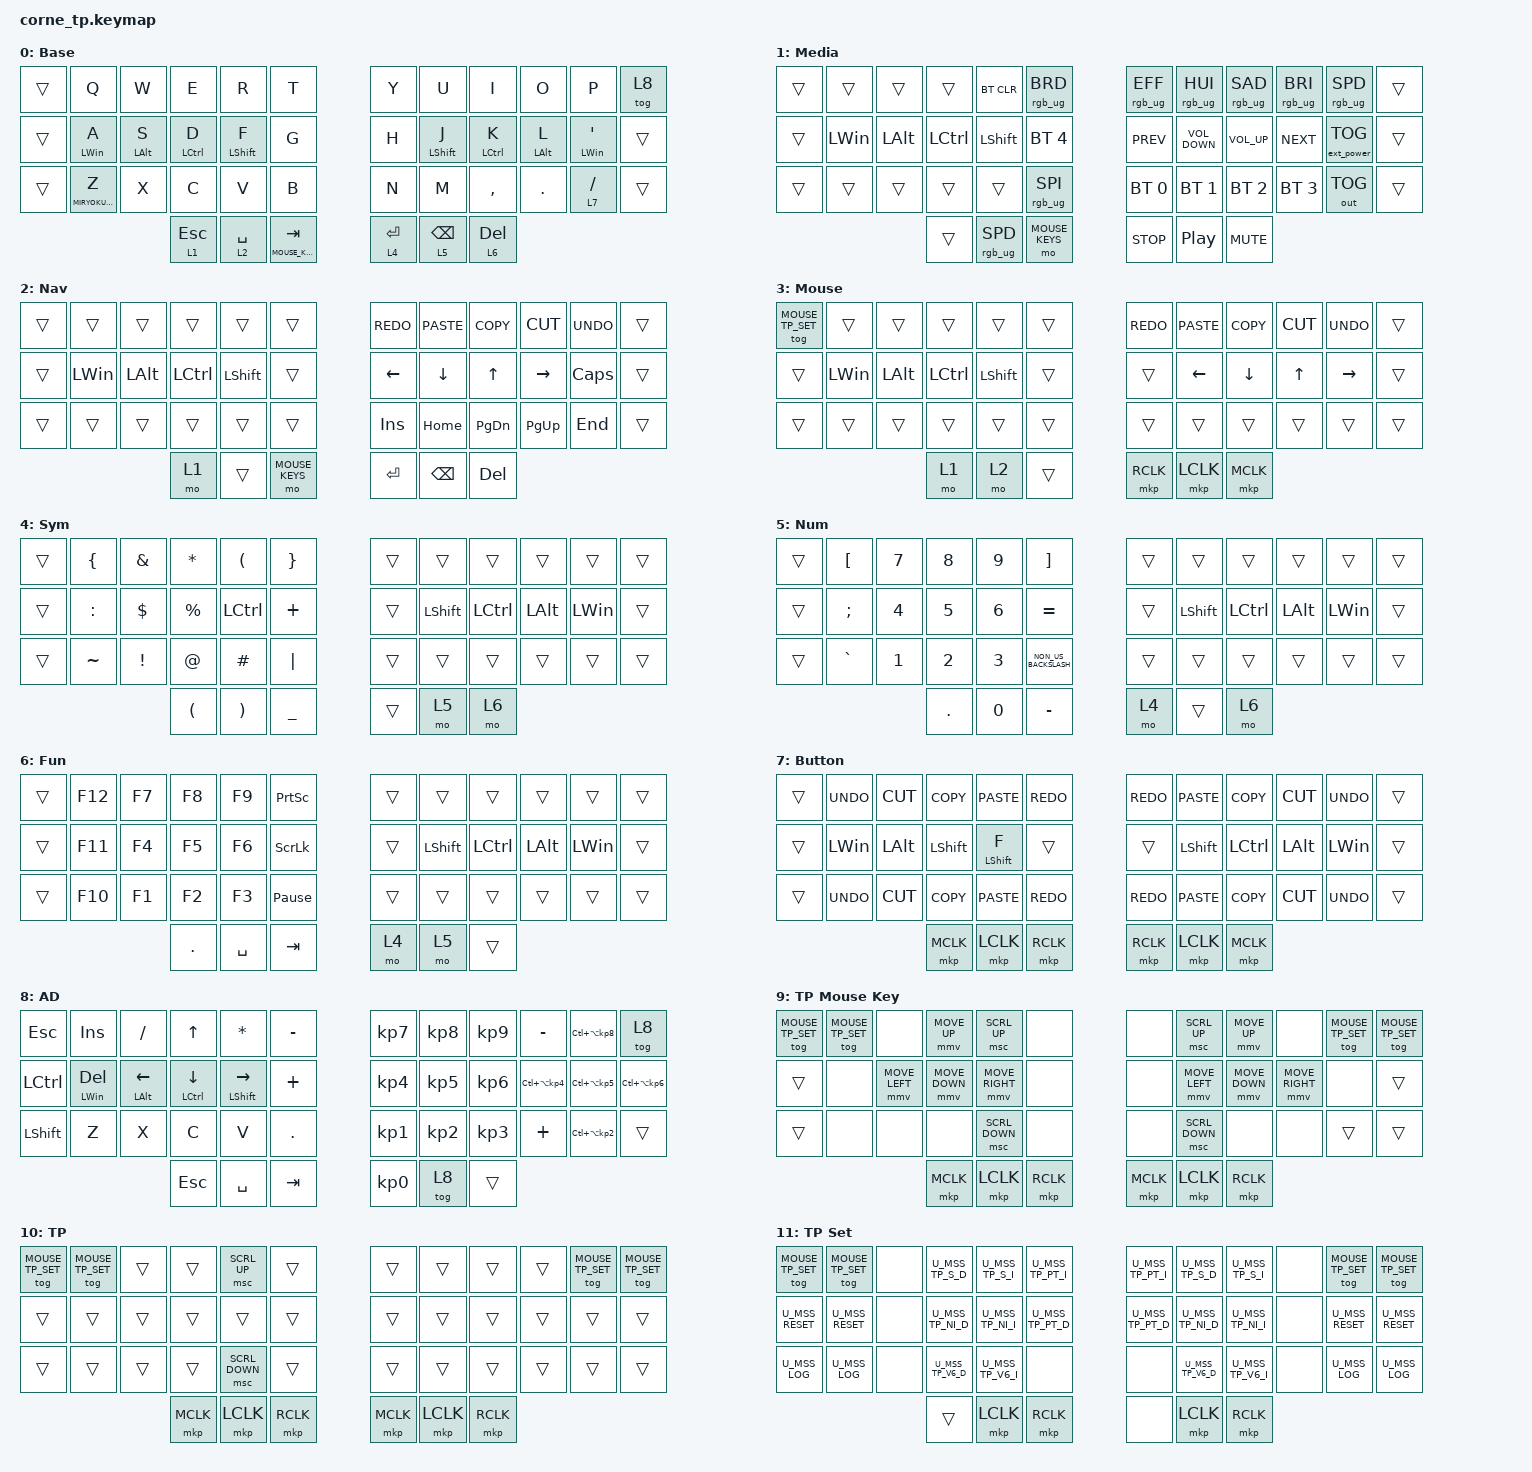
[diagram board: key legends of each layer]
/*
 * Copyright (c) 2020 The ZMK Contributors
 *
 * SPDX-License-Identifier: MIT
 */

#include <behaviors.dtsi>
#include <dt-bindings/zmk/keys.h>
#include <dt-bindings/zmk/bt.h>
// 我添加的头文件
#include <dt-bindings/zmk/mouse.h>
#include <behaviors.dtsi>
#include <dt-bindings/zmk/ext_power.h>
#include <dt-bindings/zmk/outputs.h>
#include <dt-bindings/zmk/rgb.h>

#define BASE 0
#define MIRYOKU_BASE 0
#define MIRYOKU_MEDIA 1
#define MIRYOKU_NAV 2
#define MIRYOKU_MOUSE 3
#define MIRYOKU_SYM 4
#define MIRYOKU_NUM 5
#define MIRYOKU_FUN 6
#define MIRYOKU_BUTTON 7
#define MIRYOKU_APP_AD 8
#define MOUSE_KEYS 9
#define MOUSE_TP 10
#define MOUSE_TP_SET 11

/*
 * Defines to enable/disable features
 *
 * These defines allow us to conditionally enable and disable parts of the keymap config.
 *
 * For example, if we decide to build the firmware without the mouse features, we can
 * disable all the config options that rely on those forks and modules without having
 * to edit the entire keymap file manually every time.
 */

#define HAS_MOUSE_KEYS
#define HAS_MOUSE_TP

#ifdef HAS_MOUSE_KEYS
  #include <dt-bindings/zmk/mouse.h>
  #include <behaviors/mouse_keys.dtsi>
#endif  // HAS_MOUSE_KEYS

#ifdef HAS_MOUSE_TP
  // We store the trackpoint settings in a separate file
  // to make organization a little easier.
  #include "include/mouse_tp.dtsi"
#endif  // HAS_MOUSE_TP



// Adjust layer keys based on enabled features.
//
// This prevents build errors when we build the firmware
// without the mouse keys PR or the TP module.
#ifdef HAS_MOUSE_KEYS
  #define U_THUMB_INNER &mo MOUSE_KEYS
#else
  #define U_THUMB_INNER &none
#endif  // HAS_MOUSE_KEYS

#ifdef HAS_MOUSE_TP
  #define U_TOG_TP_SET &tog MOUSE_TP_SET
#else
  #define U_TOG_TP_SET &none
#endif  // HAS_MOUSE_TP

// Disable line-wrap in your editor to see a "visualization" of the key layouts
/ {
  behaviors {
    u_mt: u_mt {
      compatible = "zmk,behavior-hold-tap";
      #binding-cells = <2>;
      tapping-term-ms = <200>;
      flavor = "tap-preferred";
      bindings = <&kp>, <&kp>;
    };
    u_lt: u_lt {
      compatible = "zmk,behavior-hold-tap";
      #binding-cells = <2>;
      tapping-term-ms = <200>;
      flavor = "tap-preferred";
      bindings = <&mo>, <&kp>;
    };
  };
  keymap {
    compatible = "zmk,keymap";

        default_layer {
            display-name = "Base";
            bindings = <
&trans  &kp Q                        &kp W       &kp E        &kp R         &kp T                 &kp Y      &kp U            &kp I         &kp O       &kp P         &tog 8
&trans  &mt LEFT_WIN A               &mt LALT S  &mt LCTRL D  &mt LSHIFT F  &kp G                 &kp H      &mt LSHIFT J     &mt LCTRL K   &mt LALT L  &mt LWIN SQT  &trans
&trans  &lt MIRYOKU_BUTTON Z         &kp X       &kp C        &kp V         &kp B                 &kp N      &kp M            &kp COMMA     &kp DOT     &lt 7 FSLH    &trans
                                     &lt 1 ESC    &lt 2 SPACE   &lt MOUSE_KEYS TAB                &lt 4 RET  &lt 5 BACKSPACE  &lt 6 DELETE
            >;
        };

        media_layer {
            display-name = "Media";
            bindings = <
&trans  &trans        &trans    &trans     &bt BT_CLR            &rgb_ug RGB_BRD              &rgb_ug RGB_EFF    &rgb_ug RGB_HUI    &rgb_ug RGB_SAD    &rgb_ug RGB_BRI  &rgb_ug RGB_SPD    &trans
&trans  &kp LEFT_WIN  &kp LALT  &kp LCTRL  &kp LSHIFT            &bt BT_SEL 4                 &kp K_PREV         &kp C_VOLUME_DOWN  &kp C_VOLUME_UP    &kp K_NEXT       &ext_power EP_TOG  &trans
&trans  &trans        &trans    &trans     &trans                &rgb_ug RGB_SPI              &bt BT_SEL 0       &bt BT_SEL 1       &bt BT_SEL 2       &bt BT_SEL 3     &out OUT_TOG       &trans
                                &trans     &rgb_ug RGB_SPD       &mo MOUSE_KEYS               &kp C_STOP         &kp C_PLAY_PAUSE   &kp K_MUTE
            >;
        };

        nav_layer {
            display-name = "Nav";
            bindings = <
&trans  &trans        &trans    &trans     &trans      &trans             &kp K_REDO      &kp K_PASTE     &kp K_COPY     &kp K_CUT        &kp K_UNDO    &trans
&trans  &kp LEFT_WIN  &kp LALT  &kp LCTRL  &kp LSHIFT  &trans             &kp LEFT_ARROW  &kp DOWN_ARROW  &kp UP_ARROW   &kp RIGHT_ARROW  &kp CAPSLOCK  &trans
&trans  &trans        &trans    &trans     &trans      &trans             &kp INSERT      &kp HOME        &kp PAGE_DOWN  &kp PAGE_UP      &kp END       &trans
                                &mo 1      &trans      &mo MOUSE_KEYS     &kp ENTER       &kp BACKSPACE   &kp DEL
            >;
        };

        mouse_layer {
            display-name = "Mouse";
            bindings = <
&tog MOUSE_TP_SET  &trans        &trans    &trans     &trans      &trans    &kp K_REDO  &kp K_PASTE     &kp K_COPY      &kp K_CUT     &kp K_UNDO       &trans
&trans             &kp LEFT_WIN  &kp LALT  &kp LCTRL  &kp LSHIFT  &trans    &trans      &kp LEFT_ARROW  &kp DOWN_ARROW  &kp UP_ARROW  &kp RIGHT_ARROW  &trans
&trans             &trans        &trans    &trans     &trans      &trans    &trans      &trans          &trans          &trans        &trans           &trans
                                           &mo 1      &mo 2       &trans    &mkp RCLK   &mkp LCLK       &mkp MCLK
            >;
        };

        sym_layer {
            display-name = "Sym";
            bindings = <
&trans  &kp LEFT_BRACE  &kp AMPERSAND    &kp ASTERISK          &kp LEFT_PARENTHESIS   &kp RIGHT_BRACE    &trans  &trans      &trans     &trans    &trans        &trans
&trans  &kp COLON       &kp DOLLAR       &kp PERCENT           &kp LCTRL              &kp PLUS           &trans  &kp LSHIFT  &kp LCTRL  &kp LALT  &kp LEFT_WIN  &trans
&trans  &kp TILDE       &kp EXCLAMATION  &kp AT_SIGN           &kp HASH               &kp PIPE           &trans  &trans      &trans     &trans    &trans        &trans
                                         &kp LEFT_PARENTHESIS  &kp RIGHT_PARENTHESIS  &kp UNDERSCORE     &trans  &mo 5       &mo 6
            >;
        };

        num_layer {
            display-name = "Num";
            bindings = <
&trans  &kp LEFT_BRACKET  &kp NUMBER_7  &kp NUMBER_8  &kp NUMBER_9  &kp RIGHT_BRACKET       &trans  &trans      &trans     &trans    &trans        &trans
&trans  &kp SEMICOLON     &kp NUMBER_4  &kp NUMBER_5  &kp NUMBER_6  &kp EQUAL               &trans  &kp LSHIFT  &kp LCTRL  &kp LALT  &kp LEFT_WIN  &trans
&trans  &kp GRAVE         &kp NUMBER_1  &kp NUMBER_2  &kp NUMBER_3  &kp NON_US_BACKSLASH    &trans  &trans      &trans     &trans    &trans        &trans
                                        &kp PERIOD    &kp N0        &kp MINUS               &mo 4   &trans      &mo 6
            >;
        };

        fun_layer {
            display-name = "Fun";
            bindings = <
&trans  &kp F12  &kp F7  &kp F8      &kp F9     &kp PRINTSCREEN    &trans  &trans      &trans     &trans    &trans        &trans
&trans  &kp F11  &kp F4  &kp F5      &kp F6     &kp SCROLLLOCK     &trans  &kp LSHIFT  &kp LCTRL  &kp LALT  &kp LEFT_WIN  &trans
&trans  &kp F10  &kp F1  &kp F2      &kp F3     &kp PAUSE_BREAK    &trans  &trans      &trans     &trans    &trans        &trans
                         &kp PERIOD  &kp SPACE  &kp TAB            &mo 4   &mo 5       &trans
            >;
        };

        button_layer {
            display-name = "Button";
            bindings = <
&trans  &kp K_UNDO    &kp K_CUT     &kp K_COPY  &kp K_PASTE   &kp K_REDO    &kp K_REDO  &kp K_PASTE  &kp K_COPY  &kp K_CUT     &kp K_UNDO    &trans
&trans  &kp LEFT_WIN  &kp LEFT_ALT  &kp LSHIFT  &mt LSHIFT F  &trans        &trans      &kp LSHIFT   &kp LCTRL   &kp LEFT_ALT  &kp LEFT_WIN  &trans
&trans  &kp K_UNDO    &kp K_CUT     &kp K_COPY  &kp K_PASTE   &kp K_REDO    &kp K_REDO  &kp K_PASTE  &kp K_COPY  &kp K_CUT     &kp K_UNDO    &trans
                                    &mkp MCLK   &mkp LCLK     &mkp RCLK     &mkp RCLK   &mkp LCLK    &mkp MCLK
            >;
        };

        ad_layer {
            display-name = "AD";
            bindings = <
&kp ESC         &kp INS           &kp FSLH                 &kp UP                &kp ASTERISK            &kp MINUS     &kp KP_NUMBER_7  &kp KP_NUMBER_8  &kp KP_NUMBER_9  &kp MINUS                &kp LC(LA(KP_NUMBER_8))  &tog 8
&kp LCTRL       &mt LEFT_WIN DEL  &mt LEFT_ALT LEFT_ARROW  &mt LCTRL DOWN_ARROW  &mt LSHIFT RIGHT_ARROW  &kp PLUS      &kp KP_NUMBER_4  &kp KP_NUMBER_5  &kp KP_NUMBER_6  &kp LC(LA(KP_NUMBER_4))  &kp LC(LA(KP_NUMBER_5))  &kp LC(LA(KP_NUMBER_6))
&kp LEFT_SHIFT  &kp Z             &kp X                    &kp C                 &kp V                   &kp PERIOD    &kp KP_NUMBER_1  &kp KP_NUMBER_2  &kp KP_NUMBER_3  &kp PLUS                 &kp LC(LA(KP_NUMBER_2))  &trans
                                                           &kp ESC               &kp SPACE               &kp TAB       &kp KP_NUMBER_0  &tog 8           &trans
            >;
        };

#ifdef HAS_MOUSE_KEYS

    MouseKeys_layer {
      display-name = "TP Mouse Key";
      bindings = <
// ╭────────────────────────┬────────────────────────┬────────────────────────┬────────────────────────┬────────────────────────┬────────────────────────╮    ╭────────────────────────┬────────────────────────┬────────────────────────┬────────────────────────┬────────────────────────┬────────────────────────╮
     U_TOG_TP_SET             U_TOG_TP_SET             &none                    &mmv MOVE_UP             &msc SCRL_UP             &none                         &none                    &msc SCRL_UP             &mmv MOVE_UP             &none                    U_TOG_TP_SET              U_TOG_TP_SET
// ├────────────────────────┼────────────────────────┼────────────────────────┼────────────────────────┼────────────────────────┼────────────────────────┤    ├────────────────────────┼────────────────────────┼────────────────────────┼────────────────────────┼────────────────────────┼────────────────────────┤
     &trans                   &none                    &mmv MOVE_LEFT           &mmv MOVE_DOWN           &mmv MOVE_RIGHT          &none                         &none                    &mmv MOVE_LEFT           &mmv MOVE_DOWN           &mmv MOVE_RIGHT          &none                     &trans
// ├────────────────────────┼────────────────────────┼────────────────────────┼────────────────────────┼────────────────────────┼────────────────────────┤    ├────────────────────────┼────────────────────────┼────────────────────────┼────────────────────────┼────────────────────────┼────────────────────────┤
     &trans                   &none                    &none                    &none                    &msc SCRL_DOWN           &none                         &none                    &msc SCRL_DOWN           &none                    &none                    &trans                    &trans
// ╰────────────────────────┴────────────────────────┴────────────────────────┴────────────────────────┼────────────────────────┼────────────────────────┤    ├────────────────────────┼────────────────────────┼────────────────────────┼────────────────────────┴────────────────────────┼────────────────────────╯
                                                                                &mkp MCLK                &mkp LCLK                &mkp RCLK                     &mkp MCLK                &mkp LCLK                &mkp RCLK
//                                                                            ╰────────────────────────┴────────────────────────┴────────────────────────╯    ╰────────────────────────┴────────────────────────┴────────────────────────╯
      >;
    };

#endif

#ifdef HAS_MOUSE_TP

    // Automatically activated when the mouse or trackpoint moves.
    // Configured in `include/mouse_tp.dtsi`.
    MouseTP_layer {
      display-name = "TP";
      bindings = <
// ╭────────────────────────┬────────────────────────┬────────────────────────┬────────────────────────┬────────────────────────┬────────────────────────╮    ╭────────────────────────┬────────────────────────┬────────────────────────┬────────────────────────┬────────────────────────┬────────────────────────╮
     U_TOG_TP_SET             U_TOG_TP_SET             &trans                   &trans                   &msc SCRL_UP             &trans                        &trans                   &trans                   &trans                   &trans                   U_TOG_TP_SET              U_TOG_TP_SET
// ├────────────────────────┼────────────────────────┼────────────────────────┼────────────────────────┼────────────────────────┼────────────────────────┤    ├────────────────────────┼────────────────────────┼────────────────────────┼────────────────────────┼────────────────────────┼────────────────────────┤
     &trans                   &trans                   &trans                   &trans                   &trans                   &trans                        &trans                   &trans                   &trans                   &trans                   &trans                    &trans
// ├────────────────────────┼────────────────────────┼────────────────────────┼────────────────────────┼────────────────────────┼────────────────────────┤    ├────────────────────────┼────────────────────────┼────────────────────────┼────────────────────────┼────────────────────────┼────────────────────────┤
     &trans                   &trans                   &trans                   &trans                   &msc SCRL_DOWN           &trans                        &trans                   &trans                   &trans                   &trans                   &trans                    &trans
// ╰────────────────────────┴────────────────────────┴────────────────────────┴────────────────────────┼────────────────────────┼────────────────────────┤    ├────────────────────────┼────────────────────────┼────────────────────────┼────────────────────────┴────────────────────────┼────────────────────────╯
                                                                                &mkp MCLK                &mkp LCLK                &mkp RCLK                     &mkp MCLK                &mkp LCLK                &mkp RCLK
//                                                                            ╰────────────────────────┴────────────────────────┴────────────────────────╯    ╰────────────────────────┴────────────────────────┴────────────────────────╯
      >;
    };

    // You can find the defines for the actual key press behaviors in `include/mouse_tp.dtsi`.
    MouseSettings_layer {
      display-name = "TP Set";
      bindings = <
// ╭────────────────────────┬────────────────────────┬────────────────────────┬────────────────────────┬────────────────────────┬────────────────────────╮    ╭────────────────────────┬────────────────────────┬────────────────────────┬────────────────────────┬────────────────────────┬────────────────────────╮
     U_TOG_TP_SET             U_TOG_TP_SET             &none                    U_MSS_TP_S_D             U_MSS_TP_S_I             U_MSS_TP_PT_I                 U_MSS_TP_PT_I            U_MSS_TP_S_D             U_MSS_TP_S_I             &none                    U_TOG_TP_SET              U_TOG_TP_SET
// ├────────────────────────┼────────────────────────┼────────────────────────┼────────────────────────┼────────────────────────┼────────────────────────┤    ├────────────────────────┼────────────────────────┼────────────────────────┼────────────────────────┼────────────────────────┼────────────────────────┤
     U_MSS_RESET              U_MSS_RESET              &none                    U_MSS_TP_NI_D            U_MSS_TP_NI_I            U_MSS_TP_PT_D                 U_MSS_TP_PT_D            U_MSS_TP_NI_D            U_MSS_TP_NI_I            &none                    U_MSS_RESET               U_MSS_RESET
// ├────────────────────────┼────────────────────────┼────────────────────────┼────────────────────────┼────────────────────────┼────────────────────────┤    ├────────────────────────┼────────────────────────┼────────────────────────┼────────────────────────┼────────────────────────┼────────────────────────┤
     U_MSS_LOG                U_MSS_LOG                &none                    U_MSS_TP_V6_D            U_MSS_TP_V6_I            &none                         &none                    U_MSS_TP_V6_D            U_MSS_TP_V6_I            &none                    U_MSS_LOG                 U_MSS_LOG
// ╰────────────────────────┴────────────────────────┴────────────────────────┴────────────────────────┼────────────────────────┼────────────────────────┤    ├────────────────────────┼────────────────────────┼────────────────────────┼────────────────────────┴────────────────────────┼────────────────────────╯
                                                                                &trans                   &mkp LCLK                &mkp RCLK                     &none                    &mkp LCLK                &mkp RCLK
//                                                                            ╰────────────────────────┴────────────────────────┴────────────────────────╯    ╰────────────────────────┴────────────────────────┴────────────────────────╯
      >;
    };

#endif
  };
};
